VERSION ""

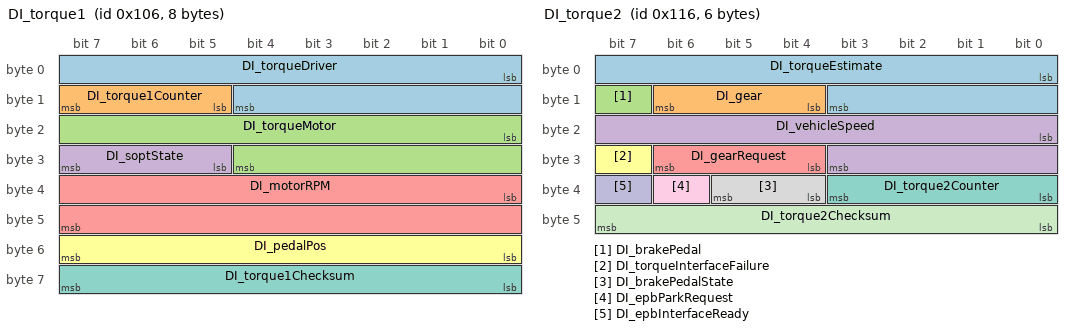
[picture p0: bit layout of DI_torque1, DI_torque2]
BO_ 262 DI_torque1: 8 DI
 SG_ DI_torqueDriver : 0|13@1- (0.25,0) [-750|750] "Nm"  NEO
 SG_ DI_torque1Counter : 13|3@1+ (1,0) [0|0] ""  NEO
 SG_ DI_torqueMotor : 16|13@1- (0.25,0) [-750|750] "Nm"  NEO
 SG_ DI_soptState : 29|3@1+ (1,0) [0|0] ""  NEO
 SG_ DI_motorRPM : 32|16@1- (1,0) [-17000|17000] "RPM"  NEO
 SG_ DI_pedalPos : 48|8@1+ (0.4,0) [0|100] "%"  NEO
 SG_ DI_torque1Checksum : 56|8@1+ (1,0) [0|0] ""  NEO

BO_ 278 DI_torque2: 6 DI
 SG_ DI_torqueEstimate : 0|12@1- (0.5,0) [-750|750] "Nm" NEO
 SG_ DI_gear : 12|3@1+ (1,0) [0|0] "" NEO
 SG_ DI_brakePedal : 15|1@1+ (1,0) [0|0] "" NEO
 SG_ DI_vehicleSpeed : 16|12@1+ (0.05,-25) [-25|179.75] "MPH" NEO
 SG_ DI_gearRequest : 28|3@1+ (1,0) [0|0] "" NEO
 SG_ DI_torqueInterfaceFailure : 31|1@1+ (1,0) [0|0] "" NEO
 SG_ DI_torque2Counter : 32|4@1+ (1,0) [0|0] "" NEO
 SG_ DI_brakePedalState : 36|2@1+ (1,0) [0|0] "" NEO
 SG_ DI_epbParkRequest : 38|1@1+ (1,0) [0|0] "" NEO
 SG_ DI_epbInterfaceReady : 39|1@1+ (1,0) [0|0] "" NEO
 SG_ DI_torque2Checksum : 40|8@1+ (1,0) [0|0] "" NEO

BO_ 504 BrakeMessage: 8 XXX
 SG_ driverBrakeStatus : 2|2@1+ (1,0) [0|3] "" XXX

BO_ 568 STW_ACTN_RQ: 8 STW
 SG_ SpdCtrlLvr_Stat : 0|6@1+ (1,0) [0|0] "" NEO
 SG_ VSL_Enbl_Rq : 6|1@1+ (1,0) [0|0] "" NEO
 SG_ SpdCtrlLvrStat_Inv : 7|1@1+ (1,0) [0|0] "" NEO
 SG_ DTR_Dist_Rq : 8|8@1+ (1,0) [0|200] "" NEO
 SG_ TurnIndLvr_Stat : 16|2@1+ (1,0) [0|0] "" NEO
 SG_ HiBmLvr_Stat : 18|2@1+ (1,0) [0|0] "" NEO
 SG_ WprWashSw_Psd : 20|2@1+ (1,0) [0|0] "" NEO
 SG_ WprWash_R_Sw_Posn_V2 : 22|2@1+ (1,0) [0|0] "" NEO
 SG_ StW_Lvr_Stat : 24|3@1+ (1,0) [0|0] "" NEO
 SG_ StW_Cond_Flt : 27|1@1+ (1,0) [0|0] "" NEO
 SG_ StW_Cond_Psd : 28|2@1+ (1,0) [0|0] "" NEO
 SG_ HrnSw_Psd : 30|2@1+ (1,0) [0|0] "" NEO
 SG_ StW_Sw00_Psd : 32|1@1+ (1,0) [0|0] "" NEO
 SG_ StW_Sw01_Psd : 33|1@1+ (1,0) [0|0] "" NEO
 SG_ StW_Sw02_Psd : 34|1@1+ (1,0) [0|0] "" NEO
 SG_ StW_Sw03_Psd : 35|1@1+ (1,0) [0|0] "" NEO
 SG_ StW_Sw04_Psd : 36|1@1+ (1,0) [0|0] "" NEO
 SG_ StW_Sw05_Psd : 37|1@1+ (1,0) [0|0] "" NEO
 SG_ StW_Sw06_Psd : 38|1@1+ (1,0) [0|0] "" NEO
 SG_ StW_Sw07_Psd : 39|1@1+ (1,0) [0|0] "" NEO
 SG_ StW_Sw08_Psd : 40|1@1+ (1,0) [0|0] "" NEO
 SG_ StW_Sw09_Psd : 41|1@1+ (1,0) [0|0] "" NEO
 SG_ StW_Sw10_Psd : 42|1@1+ (1,0) [0|0] "" NEO
 SG_ StW_Sw11_Psd : 43|1@1+ (1,0) [0|0] "" NEO
 SG_ StW_Sw12_Psd : 44|1@1+ (1,0) [0|0] "" NEO
 SG_ StW_Sw13_Psd : 45|1@1+ (1,0) [0|0] "" NEO
 SG_ StW_Sw14_Psd : 46|1@1+ (1,0) [0|0] "" NEO
 SG_ StW_Sw15_Psd : 47|1@1+ (1,0) [0|0] "" NEO
 SG_ WprSw6Posn : 48|3@1+ (1,0) [0|0] "" NEO
 SG_ MC_STW_ACTN_RQ : 52|4@1+ (1,0) [0|15] "" NEO
 SG_ CRC_STW_ACTN_RQ : 56|8@1+ (1,0) [0|0] "" NEO

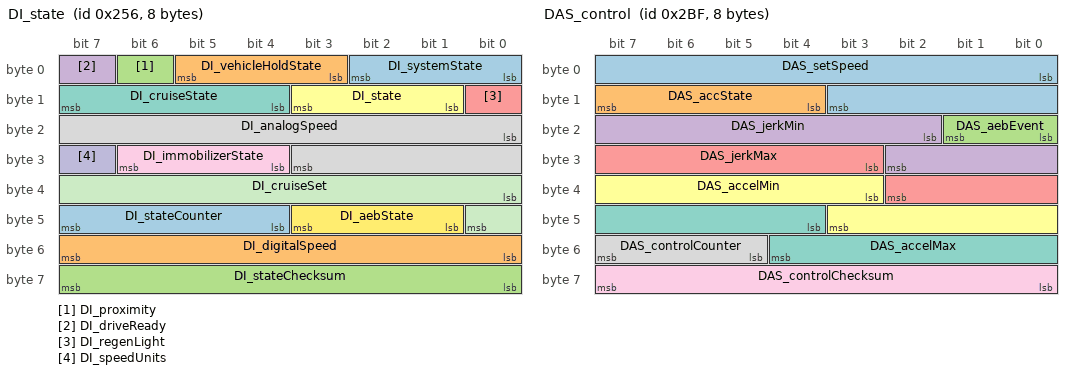
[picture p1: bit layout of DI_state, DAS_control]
BO_ 598 DI_state: 8 DI
 SG_ DI_systemState : 0|3@1+ (1,0) [0|0] ""  NEO
 SG_ DI_vehicleHoldState : 3|3@1+ (1,0) [0|0] ""  NEO
 SG_ DI_proximity : 6|1@1+ (1,0) [0|0] ""  NEO
 SG_ DI_driveReady : 7|1@1+ (1,0) [0|0] ""  NEO
 SG_ DI_regenLight : 8|1@1+ (1,0) [0|0] ""  NEO
 SG_ DI_state : 9|3@1+ (1,0) [0|0] ""  NEO
 SG_ DI_cruiseState : 12|4@1+ (1,0) [0|0] ""  NEO
 SG_ DI_analogSpeed : 16|12@1+ (0.1,0) [0|150] "speed"  NEO
 SG_ DI_immobilizerState : 28|3@1+ (1,0) [0|0] ""  NEO
 SG_ DI_speedUnits : 31|1@1+ (1,0) [0|1] ""  NEO
 SG_ DI_cruiseSet : 32|9@1+ (0.5,0) [0|255.5] "speed"  NEO
 SG_ DI_aebState : 41|3@1+ (1,0) [0|0] ""  NEO
 SG_ DI_stateCounter : 44|4@1+ (1,0) [0|0] ""  NEO
 SG_ DI_digitalSpeed : 48|8@1+ (1,0) [0|250] ""  NEO
 SG_ DI_stateChecksum : 56|8@1+ (1,0) [0|0] ""  NEO

BO_ 703 DAS_control: 8 GTW
 SG_ DAS_setSpeed : 0|12@1+ (0.1,0) [0|409.4] "kph" DI,PM,APS
 SG_ DAS_accState : 12|4@1+ (1,0) [0|0] "" DI,PM,APS
 SG_ DAS_aebEvent : 16|2@1+ (1,0) [0|3] "" DI,PM,APS
 SG_ DAS_jerkMin : 18|9@1+ (0.03,-15.232) [-15.232|0.098] "m/s^3" DI,PM,APS
 SG_ DAS_jerkMax : 27|8@1+ (0.059,0) [0|15.045] "m/s^3" DI,PM,APS
 SG_ DAS_accelMin : 35|9@1+ (0.04,-15) [-15|5.44] "m/s^2" DI,PM,APS
 SG_ DAS_accelMax : 44|9@1+ (0.04,-15) [-15|5.44] "m/s^2" DI,PM,APS
 SG_ DAS_controlCounter : 53|3@1+ (1,0) [0|0] "" DI,PM,APS
 SG_ DAS_controlChecksum : 56|8@1+ (1,0) [0|0] "" DI,PM,APS

BU_: ADAS RADAR NEO XXX

CM_ "AUTOGENERATED FILE, DO NOT EDIT";

CM_ "Imported file _comma.dbc starts here";
CM_ "BO_ STEERING_IPAS_COMMA: Copy of msg 614 so we can do angle control while the Park Assist ECU is connected (Panda spoofs 614 with 359 on connector J70). Note that addresses 0x266 and 0x167 are checksum-invariant";

CM_ "BO_ SECONDARY_STEER_ANGLE: ZSS is a high-precision steering angle sensor that can replace the lower resolution sensor in most TSS1 Toyotas. Learn more: https://github.com/commaai/openpilot/wiki/Toyota-Lexus#zorro-steering-sensor-zss";

CM_ "BO_ SDSU: The sDSU is a modified DSU for use in TSS1 Toyotas. Learn more: https://github.com/wocsor/panda/tree/smart_dsu";
CM_ SG_ 767 FD_BUTTON "The follow distance button signal as forwarded by the sdsu";

CM_ "Imported file _toyota_2017.dbc starts here";
CM_ SG_ 36 YAW_RATE "verify";
CM_ SG_ 36 ACCEL_X "x-axis accel";
CM_ SG_ 37 STEER_FRACTION "1/15th of the signal STEER_ANGLE, which is 1.5 deg; note that 0x8 is never set";
CM_ SG_ 37 STEER_RATE "factor is tbd";
CM_ SG_ 466 NEUTRAL_FORCE "force in newtons the engine/electric motors are applying without any acceleration commands or user input";
CM_ SG_ 466 ACC_BRAKING "whether brakes are being actuated from ACC command";
CM_ SG_ 466 ACCEL_NET "net acceleration produced by the system, given ACCEL_CMD, road grade and other factors";
CM_ SG_ 466 CRUISE_STATE "Active state is 8, if standstill is requested will switch to state 11(3 sec timer), after timer is elapsed will switch into state 7(standstill). If plus button was pressed - status 9, minus button pressed - status 10";
CM_ SG_ 467 ACC_FAULTED "1 when ACC is faulted and the PCM disallows engagement";
CM_ SG_ 467 SET_SPEED "43 km/h are shown as 28 mph, so conversion isn't perfect";
CM_ SG_ 467 LOW_SPEED_LOCKOUT "in low speed lockout, system would always disengage below 28mph";
CM_ SG_ 560 BRAKE_PRESSED "another brake pressed?";
CM_ SG_ 581 GAS_PEDAL "it seems slightly filtered";
CM_ SG_ 608 STEER_TORQUE_DRIVER "driver torque";
CM_ SG_ 608 STEER_OVERRIDE "set when driver torque exceeds a certain value";
CM_ SG_ 614 ANGLE "set to measured angle when ipas control isn't active";
CM_ SG_ 643 _COUNTER "only used on cars that use this msg for cruise control";
CM_ SG_ 643 BRAKE_STATUS "only used on cars that use this msg for cruise control";
CM_ SG_ 643 PRECOLLISION_ACTIVE "set 0.5s before any braking";
CM_ SG_ 835 ACC_TYPE "if 2, car is likely to have a permanent low speed lockout. 1 is ok";
CM_ SG_ 835 RADAR_DIRTY "Display Clean Radar Sensor message on HUD";
CM_ SG_ 835 ACC_MALFUNCTION "display ACC fault on dash if set to 1";
CM_ SG_ 835 ACC_CUT_IN "Display blinking yellow lead if set to 1";
CM_ SG_ 835 DISTANCE "Cycle through ACC following distance from long, mid, short when set to 1";
CM_ SG_ 835 ITS_CONNECT_LEAD "Displayed when lead car is capable of ITS Connect";
CM_ SG_ 835 ALLOW_LONG_PRESS "Enable Toyota's factory set speed increment behaviour, available on both metrics cars and imperial unit cars";
CM_ SG_ 835 PERMIT_BRAKING "Original ACC has this going high when a car in front is detected. In openpilot and before the PERMIT_BRAKING name, this was 'SET_ME_1' and is hardcoded to be high. Unsure if only informational or has an effect though existing usage in openpilot is to always set it to 1. Originally 'PMTBRKG' in the leaked toyota_2017_ref_pt.dbc file and name expansion speculated to be PerMiT BRaKinG.";
CM_ SG_ 835 ACCEL_CMD_ALT "Copy of main ACCEL_CMD, but across 8 bits instead of 16 bits like ACCEL_CMD. Unsure if only informational or has an effect. Likely informational as existing openpilot sets this to 0 and no loss of functionality observed. Originally 'AT_RAW' in leaked toyota_2017_ref_pt.dbc file.";
CM_ SG_ 865 GAS_PEDAL_ALT "copy of main GAS_PEDAL. Both use 8 bits. Might indicate that this message is for pedals.";
CM_ SG_ 865 CLUTCH_RELEASED "boolean of clutch for 6MT.";
CM_ SG_ 865 ACC_FAULTED "1 when ACC is faulted and the PCM disallows engagement. Also describes a lockout when the ACC_CONTROL->ACC_MALFUNCTION bit is set.";
CM_ SG_ 921 UI_SET_SPEED "set speed shown in the vehicle's UI with the vehicle's unit";
CM_ SG_ 921 TEMP_ACC_FAULTED "1 when the UI is displaying or playing fault-related alerts or sounds. Also 1 when pressing main on.";
CM_ SG_ 951 BRAKE_LIGHTS_ACC "brake lights when ACC commands decel";
CM_ SG_ 956 GEAR "on 6MT, only R shows.";
CM_ SG_ 1009 UI_SET_SPEED "units seem to be whatever the car is set to";
CM_ SG_ 1041 PCS_INDICATOR "Pre-Collision System Indicator";
CM_ SG_ 1041 PCS_SENSITIVITY "Pre-Collision System Sensitivity";
CM_ SG_ 1041 PCS_DUST "alert: Front Camera Low Visibility Unavailable See Owner's Manual";
CM_ SG_ 1041 PCS_DUST2 "alert: Pre-Collision System Radar Sensor Blocked Unavailable Clean Radar Sensor";
CM_ SG_ 1041 PCS_TEMP "alert: Front Camera Out of Temperature Range Unavailable Wait until Normal Temperature";
CM_ SG_ 1041 PCS_TEMP2 "alert: Pre-Collision System Out of Temperature Range Unavailable See Owner's Manual";
CM_ SG_ 1041 FRD_ADJ "alert: ERROR ADJUSTING FRONT RADAR BEAM";
CM_ SG_ 1042 LDA_SA_TOGGLE "LDA Steering Assist Toggle";
CM_ SG_ 1042 LDW_EXIST "Unclear what this is, it's usually set to 0";
CM_ SG_ 1042 LDA_SENSITIVITY "LDA Sensitivity";
CM_ SG_ 1042 LDA_ON_MESSAGE "Display LDA Turned ON message";
CM_ SG_ 1042 REPEATED_BEEPS "LDA audible warning";
CM_ SG_ 1042 LDA_UNAVAILABLE_QUIET "LDA toggles and sensitivity settings are greyed out if set to 1";
CM_ SG_ 1042 LDA_MESSAGES "Various LDA Messages";
CM_ SG_ 1042 LDA_FRONT_CAMERA_BLOCKED "originally LDAFCVB, LDA related settings are greyed out if set to 1";
CM_ SG_ 1042 TAKE_CONTROL "Please Control Steering Wheel warning";
CM_ SG_ 1042 LANE_SWAY_TOGGLE "Lane Sway Warning System SWS Switch";
CM_ SG_ 1042 LANE_SWAY_WARNING "Lane Sway Warning System Triggered";
CM_ SG_ 1042 LANE_SWAY_FLD "Unknown signal for Lane Sway Warning System, set to 7 on stock system when SWS is enabled, 0 when SWS is disabled";
CM_ SG_ 1042 LANE_SWAY_BUZZER "Similar to TWO_BEEPS";
CM_ SG_ 1042 SET_ME_X01 "empty bit on leaked dbc, always set to 1 during normal operations";
CM_ SG_ 1042 SET_ME_X02 "empty bit on leaked dbc, always set to 2 during normal operations";
CM_ SG_ 1083 STATE "when the dashboard button is pressed, the value changes from zero to non-zero";
CM_ SG_ 1161 SPDVAL1 "Numbers 0-199 is displayed, 200-254 displays circle without number and 255 is for no limit.";
CM_ SG_ 1161 SYNCID1 "counter from 1 to f at 1 Hz";
CM_ SG_ 1161 SPDVAL2 "conditional speed value 70";
CM_ SG_ 1162 SGNNUMP "1 if SPDVAL1 is set, otherwise 0";
CM_ SG_ 1162 SYNCID2 "counter from 1 to f at 1 Hz";
CM_ SG_ 1163 TSREQPD "always 1";
CM_ SG_ 1163 TSRMSW "always 1";
CM_ SG_ 1163 OTSGNNTM "always 3";
CM_ SG_ 1163 NTLVLSPD "always 3";
CM_ SG_ 1163 OVSPNTM "always 3";
CM_ SG_ 1163 OVSPVALL "-5 at start then 2 after 2 seconds";
CM_ SG_ 1163 OVSPVALM "-5 at start then 5 after 2 seconds";
CM_ SG_ 1163 OVSPVALH "-5 at start then 10 after 2 seconds";
CM_ SG_ 1163 TSRSPU "always 1";
CM_ SG_ 1552 UI_SPEED "Does not appear to match dash";
CM_ SG_ 1552 METER_SLIDER_BRIGHTNESS_PCT "Combination display brightness setting, scales from 12 per cent to 100 per cent, reflects combination meter settings only, not linked with headlight state";
CM_ SG_ 1552 METER_SLIDER_LOW_BRIGHTNESS "Combination display low brightness mode, also controls footwell lighting";
CM_ SG_ 1552 METER_SLIDER_DIMMED "Combination display slider not at max, reflects combination meter settings only, not linked with headlight state";
CM_ SG_ 1553 ODOMETER "Unit is dependent upon units signal";
CM_ SG_ 1592 LOCK_STATUS_CHANGED "1 on rising edge of lock/unlocking";
CM_ SG_ 1592 LOCK_STATUS "The next 3 bits always seem to follow this signal.";
CM_ SG_ 1592 LOCKED_VIA_KEYFOB "1 for as long as car is locked with key fob or door handle touch";

CM_ "toyota_tnga_k_pt.dbc starts here";

CM_ SG_ 550 BRAKE_PRESSURE "seems prop to pedal force";
CM_ SG_ 550 BRAKE_POSITION "seems proportional to pedal displacement, unclear the max value of 0x1c8";
CM_ SG_ 610 TYPE "seems 1 on Corolla, 0 on all others";

VAL_ 274923520 DriverDoorOpened 1 "Opened" 0 "Closed" ;
VAL_ 270581760 RightBlinker 1 "Active" 0 "Inactive" ;
VAL_ 270581760 LeftBlinker 1 "Active" 0 "Inactive" ;
VAL_ 270581760 BlinkerLight 1 "Active" 0 "Inactive" ;
VAL_ 271368192 GearShifter 3 "Park" 0 "Drive/Low" ;
VAL_ 271360000 CruiseControlActive 1 "Active" 0 "Inactive" ;
VAL_ 276135936 CruiseButtons 6 "Cancel" 5 "Main" 3 "Set" 2 "Resume" 1 "None" ;
VAL_ 276127744 LKAGapButton 2 "???" 1 "??" 0 "None" ;
VAL_ 275955897 BSM_Indicator_Light 0 "Disabled" 1 "Enabled";
